# ESP32S31_RADIO register map
Vendor: Espressif; Series: ESP32-S31; File version: 3.52
Registers are 32-bit, read-write, no defined reset value unless marked. A register's access mark holds for its fields unless they carry their own. Offsets are from the block's base; [hi:lo] are bit positions; 'fields as' and 'values as' point back to an identical list.

## PHY_AGC_RECOVERED_GAPS — Sparse AGC words absent from the public platform PAC.
Base 0x20107000
0x10 RX_SENSE_WORD_0_OPAQUE — Read-modify-written by complete phy_rx_sense_set and saved/restored by complete phy_dig_reg_backup.
0x14 RX_SENSE_WORD_1_OPAQUE — Read-modify-written by complete phy_rx_sense_set and saved/restored by complete phy_dig_reg_backup.
0x1C CCA_CONTROL_OPAQUE — Read and written by complete CCA accessors and saved/restored by complete phy_dig_reg_backup; fields remain unnamed.
0x50 NOISE_FLOOR_STATUS_OPAQUE access not given — Complete phy_get_noise_floor reads this word; hardware access semantics remain unknown.
0x6C RSSI_STATUS_OPAQUE access not given — Complete phy_get_rssi reads this word; hardware access semantics remain unknown.
0x74 CHANNEL_FILTER_CONTROL_OPAQUE — Complete phy_chan_filt_set read-modify-writes this word and complete phy_dig_reg_backup saves/restores it.
0xCC BACKUP_WORD_CC_OPAQUE — Complete phy_dig_reg_backup saves and restores this word; all field semantics remain unknown.
0xF4 RIFS_MODE_CONTROL_OPAQUE — Complete phy_wifi_rifs_mode_en read-modify-writes bit zero; all other fields remain unknown.
0x108 RX_SENSE_BACKUP_WORD_OPAQUE — Read by complete phy_rx_sense_set and saved/restored by complete phy_dig_reg_backup; field semantics remain unknown.
0x430 CFO_CONFIG_WORD_1_OPAQUE — Complete phy_bb_cfo_cfg replaces this word and independently read-modify-writes bit 27; the hardware field meaning remains unknown.
  [27] BIT_27_CONTROL_UNKNOWN
0x434 CFO_CONFIG_WORD_2_OPAQUE — Complete phy_bb_cfo_cfg reads and replaces this word; individual hardware fields remain unnamed.
0x438 CFO_CONFIG_WORD_3_OPAQUE — Complete phy_bb_cfo_cfg reads and replaces this word; individual hardware fields remain unnamed.

## PHY_NRX_RECOVERED_GAPS — Sparse NRX words absent from the public platform PAC.
Base 0x20107800
0x00 FFT_SCALE_CONTROL_OPAQUE — Complete phy_fft_scale_force read-modify-writes this word; individual fields remain unnamed.
0x0C BACKUP_WORD_0C_OPAQUE — Complete phy_dig_reg_backup saves and restores this word; all field semantics remain unknown.
0x30 ONE_TONE_SPUR_CONTROL_OPAQUE — Complete phy_spur_reg_write_one_tone reads and replaces this word on three control-flow paths; individual hardware fields remain unnamed.
0x98 FREQUENCY_CORRECTION_CONTROL_OPAQUE — Complete phy_freq_correct read-modify-writes this word; individual fields remain unnamed.
0xB8 CFO_HIGH_CONTROL_OPAQUE — Complete phy_bb_cfo_cfg replaces bits 31:29 with the observed constant pattern while preserving bits 28:0; the hardware field meaning remains unknown.
  [31:29] HIGH_MODE_UNKNOWN
0x104 CHANNEL_FILTER_CONTROL_OPAQUE — Complete phy_chan_filt_set read-modify-writes this word and complete phy_dig_reg_backup saves/restores it.

## PHY_BB_RECOVERED_GAPS — Sparse BB words absent from the public platform PAC.
Base 0x20107C00
0x14 SPUR_COEFFICIENT_CONTROL_0_OPAQUE — Complete phy_spur_coef_cfg clears bit 13 through two read-modify-write paths; all hardware field names remain unknown.
  [13] BIT_13_CONTROL_UNKNOWN
0x58 CCA_COUNTER_CONTROL_OPAQUE — Complete phy_set_cca_cnt read-modify-writes this word; individual fields remain unnamed.
0x5C CCA_COUNTER_STATUS_0_OPAQUE access not given — Complete phy_get_cca_cnt reads this word; hardware access semantics remain unknown.
0x60 CCA_COUNTER_STATUS_1_OPAQUE access not given — Complete phy_get_cca_cnt reads this word; hardware access semantics remain unknown.
0xE8 CFO_CONFIG_WORD_4_OPAQUE — Complete phy_bb_cfo_cfg reads and replaces this word; individual hardware fields remain unnamed.
0xEC CFO_CONFIG_WORD_5_OPAQUE — Complete phy_bb_cfo_cfg replaces this word and independently read-modify-writes bit 12; the hardware field meaning remains unknown.
  [12] BIT_12_CONTROL_UNKNOWN

## PHY_BRX_RECOVERED_GAPS — Sparse BRX words absent from the public platform PAC.
Base 0x20108000
0x50 FREQUENCY_CORRECTION_CONTROL_OPAQUE — Complete phy_freq_correct read-modify-writes this word; individual fields remain unnamed.

## IEEE802154_INTERRUPT_ROUTE — The two CPU interrupt-matrix words for ESP32-S31 modem source 132 (MODEM_ZB_MAC). This source-specific view is retained with the IEEE 802.15.4 owner and publishes only the generated field readers needed to prove that a polled or validation transaction starts with both CPU routes detached.
Base 0x20585210
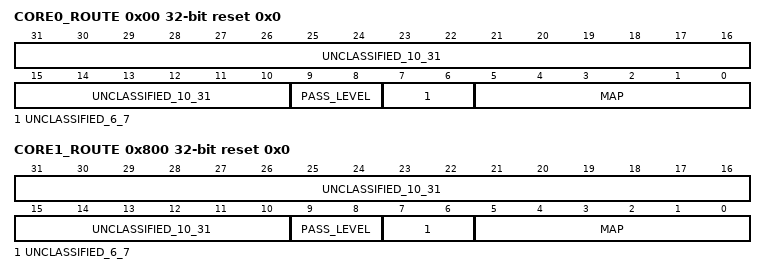
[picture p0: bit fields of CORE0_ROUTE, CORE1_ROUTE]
0x00 CORE0_ROUTE reset 0x0 — Core-zero destination and privilege routing for MODEM_ZB_MAC.
  [31:10] UNCLASSIFIED_10_31 — Unassigned bits retained solely so reset-state observation cannot erase an unexpected nonzero value.
  [9:8] PASS_LEVEL — Privilege pass/remap level selected for the peripheral source.
  [7:6] UNCLASSIFIED_6_7 — Unassigned bits retained solely so reset-state observation cannot erase an unexpected nonzero value.
  [5:0] MAP — CPU-interrupt destination selected for the peripheral source.
0x800 CORE1_ROUTE reset 0x0 — Core-one destination and privilege routing for MODEM_ZB_MAC.
  fields as CORE0_ROUTE
